VERSION ""

NS_ :

BS_:

BU_: XXX

BO_ 55 untitled: 8 XXX

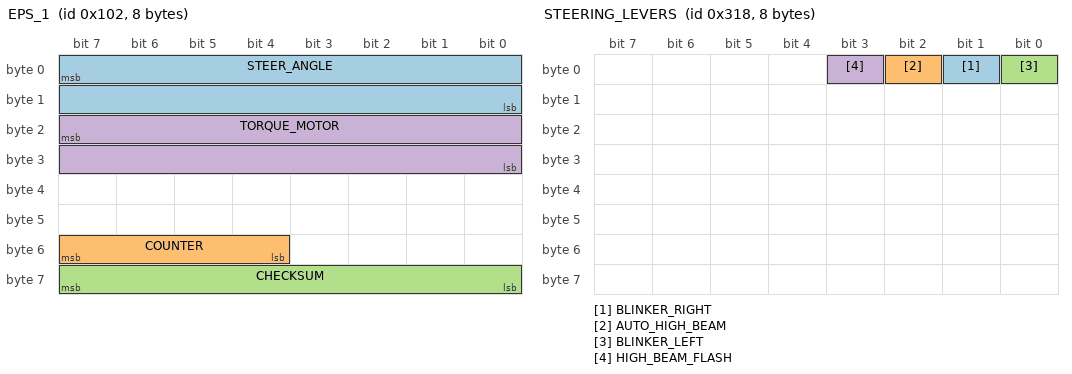
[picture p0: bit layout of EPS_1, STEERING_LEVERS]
BO_ 258 EPS_1: 8 XXX
 SG_ STEER_ANGLE : 7|16@0+ (1,0) [0|65535] "" XXX
 SG_ COUNTER : 55|4@0+ (1,0) [0|15] "" XXX
 SG_ CHECKSUM : 63|8@0+ (1,0) [0|255] "" XXX
 SG_ TORQUE_MOTOR : 23|16@0+ (1,0) [0|65535] "" XXX

BO_ 264 PCM: 8 XXX
 SG_ RPM : 7|16@0+ (1,0) [0|65535] "" XXX

BO_ 792 STEERING_LEVERS: 8 XXX
 SG_ BLINKER_RIGHT : 1|1@0+ (1,0) [0|1] "" XXX
 SG_ AUTO_HIGH_BEAM : 2|1@0+ (1,0) [0|1] "" XXX
 SG_ BLINKER_LEFT : 0|1@0+ (1,0) [0|1] "" XXX
 SG_ HIGH_BEAM_FLASH : 3|1@0+ (1,0) [0|1] "" XXX

BO_ 464 OCCUPANT_RESTRAINT_MODULE: 8 XXX
 SG_ DRIVER_SEATBELT_STATUS : 16|1@0+ (1,0) [0|1] "" XXX

BO_ 280 NEW_MSG_1: 8 XXX
 SG_ NEW_SIGNAL_1 : 15|16@0+ (1,0) [0|65535] "" XXX
 SG_ NEW_SIGNAL_2 : 31|16@0+ (1,0) [0|65535] "" XXX

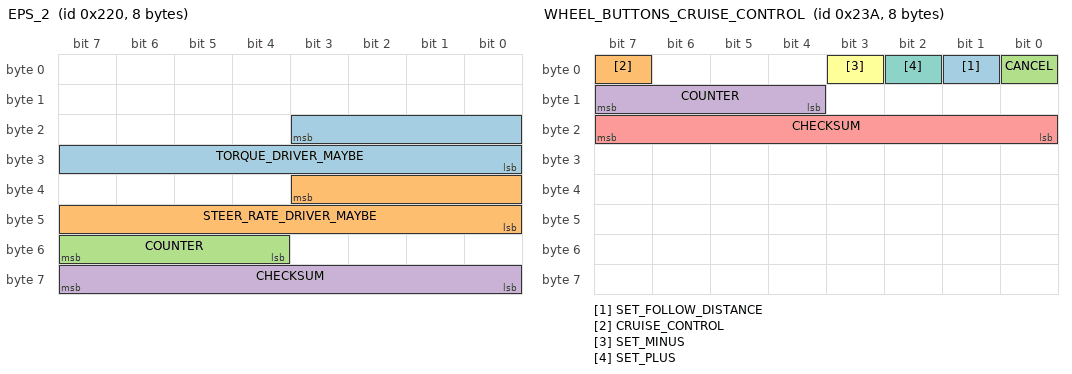
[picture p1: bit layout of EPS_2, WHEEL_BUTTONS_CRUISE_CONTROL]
BO_ 544 EPS_2: 8 XXX
 SG_ TORQUE_DRIVER_MAYBE : 19|12@0+ (1,0) [0|255] "" XXX
 SG_ STEER_RATE_DRIVER_MAYBE : 35|12@0+ (1,0) [0|255] "" XXX
 SG_ COUNTER : 55|4@0+ (1,0) [0|15] "" XXX
 SG_ CHECKSUM : 63|8@0+ (1,0) [0|255] "" XXX

BO_ 570 WHEEL_BUTTONS_CRUISE_CONTROL: 8 XXX
 SG_ SET_FOLLOW_DISTANCE : 1|1@0+ (1,0) [0|1] "" XXX
 SG_ CRUISE_CONTROL : 7|1@0+ (1,0) [0|63] "" XXX
 SG_ CANCEL : 0|1@0+ (1,0) [0|1] "" XXX
 SG_ COUNTER : 15|4@0+ (1,0) [0|15] "" XXX
 SG_ CHECKSUM : 23|8@0+ (1,0) [0|255] "" XXX
 SG_ SET_MINUS : 3|1@0+ (1,0) [0|31] "" XXX
 SG_ SET_PLUS : 2|1@0+ (1,0) [0|1] "" XXX

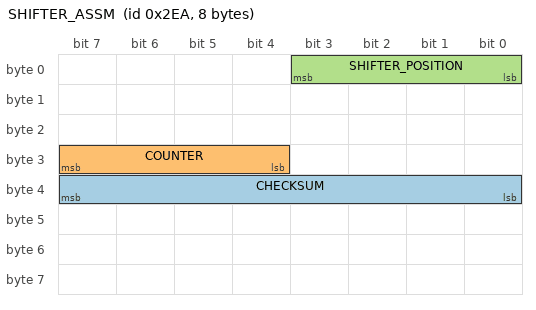
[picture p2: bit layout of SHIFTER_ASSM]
BO_ 746 SHIFTER_ASSM: 8 XXX
 SG_ CHECKSUM : 39|8@0+ (1,0) [0|255] "" XXX
 SG_ COUNTER : 31|4@0+ (1,0) [0|15] "" XXX
 SG_ SHIFTER_POSITION : 0|4@1+ (1,0) [0|7] "" XXX

CM_ SG_ 792 AUTO_HIGH_BEAM "1 on 0 off";
CM_ SG_ 464 DRIVER_SEATBELT_STATUS "0 buckled";
